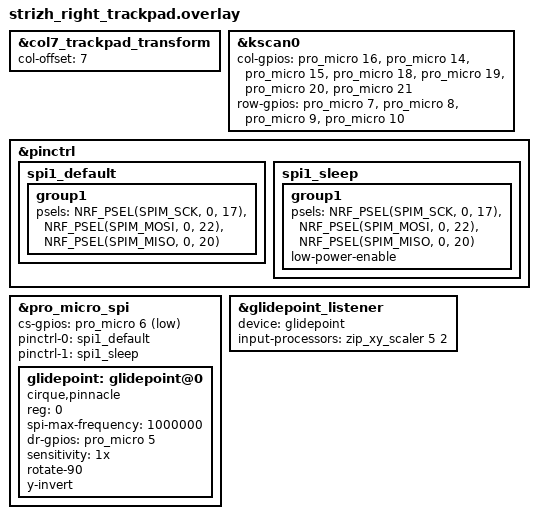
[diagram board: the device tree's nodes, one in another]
#include "strizh.dtsi"

#include <input/processors.dtsi>
#include <dt-bindings/zmk/input_transform.h>
#include <dt-bindings/input/input-event-codes.h>

&col7_trackpad_transform {
    col-offset = <7>;
};

&kscan0 {
    col-gpios
        = <&pro_micro 16 GPIO_ACTIVE_HIGH>   // col7
        , <&pro_micro 14 GPIO_ACTIVE_HIGH>   // col6
        , <&pro_micro 15 GPIO_ACTIVE_HIGH>   // col5
        , <&pro_micro 18 GPIO_ACTIVE_HIGH>   // col4
        , <&pro_micro 19 GPIO_ACTIVE_HIGH>   // col3
        , <&pro_micro 20 GPIO_ACTIVE_HIGH>   // col2
        , <&pro_micro 21 GPIO_ACTIVE_HIGH>   // col1
        ;

    row-gpios
        = <&pro_micro  7 (GPIO_ACTIVE_HIGH | GPIO_PULL_DOWN)>   // row1
        , <&pro_micro  8 (GPIO_ACTIVE_HIGH | GPIO_PULL_DOWN)>   // row2
        , <&pro_micro  9 (GPIO_ACTIVE_HIGH | GPIO_PULL_DOWN)>   // row3
        , <&pro_micro 10 (GPIO_ACTIVE_HIGH | GPIO_PULL_DOWN)>   // row4
        ;
};

&pinctrl {
    spi1_default: spi1_default {
        group1 {
            psels = <NRF_PSEL(SPIM_SCK, 0, 17)>,
                <NRF_PSEL(SPIM_MOSI, 0, 22)>,
                <NRF_PSEL(SPIM_MISO, 0, 20)>;
        };
    };

    spi1_sleep: spi1_sleep {
        group1 {
            psels = <NRF_PSEL(SPIM_SCK, 0, 17)>,
                <NRF_PSEL(SPIM_MOSI, 0, 22)>,
                <NRF_PSEL(SPIM_MISO, 0, 20)>;
            low-power-enable;
        };
    };
};

&pro_micro_spi {
    status = "okay";
    cs-gpios = <&pro_micro 6 GPIO_ACTIVE_LOW>;
    pinctrl-0 = <&spi1_default>;
    pinctrl-1 = <&spi1_sleep>;
    pinctrl-names = "default", "sleep";

    glidepoint: glidepoint@0 {
        compatible = "cirque,pinnacle";
        reg = <0>;
        spi-max-frequency = <1000000>;
        status = "okay";
        dr-gpios = <&pro_micro 5 GPIO_ACTIVE_HIGH>;

        sensitivity = "1x";
        rotate-90;
        y-invert;
        //sleep;
    };
};

&glidepoint_listener {
    status = "okay";
    device = <&glidepoint>;
    input-processors = <&zip_xy_scaler 5 2>;
};
